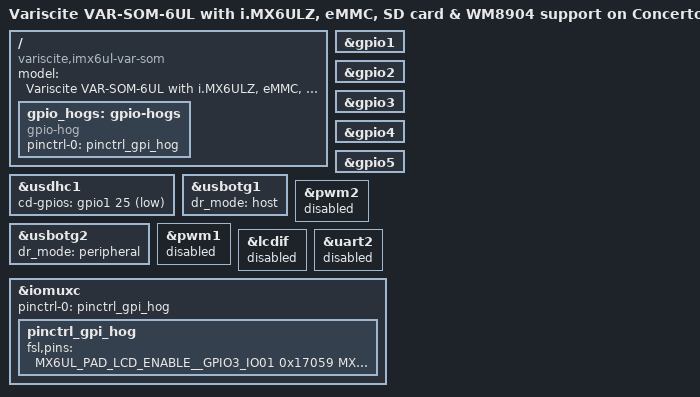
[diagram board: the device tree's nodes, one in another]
/*
 * Copyright (C) 2024 Variscite Ltd. - https://www.variscite.com
 *
 * This program is free software; you can redistribute it and/or modify
 * it under the terms of the GNU General Public License version 2 as
 * published by the Free Software Foundation.
 */

/dts-v1/;

#include "imx6ulz.dtsi"

#include "imx6ulz-var-som.dtsi"
#include "imx6ul-imx6ull-var-som-emmc.dtsi"

#include "imx6ulz-var-som-concerto-board.dtsi"
#include "imx6ul-imx6ull-var-som-concerto-board-sd-card.dtsi"

/ {
        model = "Variscite VAR-SOM-6UL with i.MX6ULZ, eMMC, SD card & WM8904 support on Concerto-Board";
        compatible = "variscite,imx6ul-var-som", "fsl,imx6ulz";

        gpio_hogs: gpio-hogs {
        compatible = "gpio-hog";
        pinctrl-names = "default";
        pinctrl-0 = <&pinctrl_gpi_hog>;
        };
};

&usdhc1 {
        status = "okay";
        cd-gpios = <&gpio1 25 GPIO_ACTIVE_LOW>;
};


&gpio1 {
    status = "okay";
};

&gpio2 {  
    status = "okay";
};

&gpio3 {
    status = "okay";
};

&gpio4 {
    status = "okay";
};

&gpio5 {
    status = "okay";
};


&usbotg1 {
    dr_mode = "host";  // Set the USB OTG controller to Host mode
    status = "okay";
};
&usbotg2 {
    dr_mode = "peripheral";  // Set the USB OTG2 to peripheral mode
    status = "okay";
};


&pwm2 {
        status = "disabled";
};

&pwm1 {
        status = "disabled";
};

&lcdif {
        status = "disabled";
};

&uart2 {
        status = "disabled";
};


&iomuxc {

  pinctrl-names = "default";
  pinctrl-0 = <&pinctrl_gpi_hog>;
  pinctrl_gpi_hog: pinctrl_gpi_hog {
      fsl,pins = <
          MX6UL_PAD_LCD_ENABLE__GPIO3_IO01         0x17059  // USBH_PWREN
          MX6UL_PAD_SNVS_TAMPER8__GPIO5_IO08       0x17059  // USBH_FAULT
          
      >;
  };

};
